# MDR1986VK01 register map
File version: 1.0.2
Registers are 32-bit, read-write, no defined reset value unless marked. A register's access mark holds for its fields unless they carry their own. Offsets are from the block's base; [hi:lo] are bit positions; {n}, {i} and the like mark numbered series; 'fields as' and 'values as' point back to an identical list.

## MDR_ADC0 — MDR_ADC0 description
Base 0x400A7000
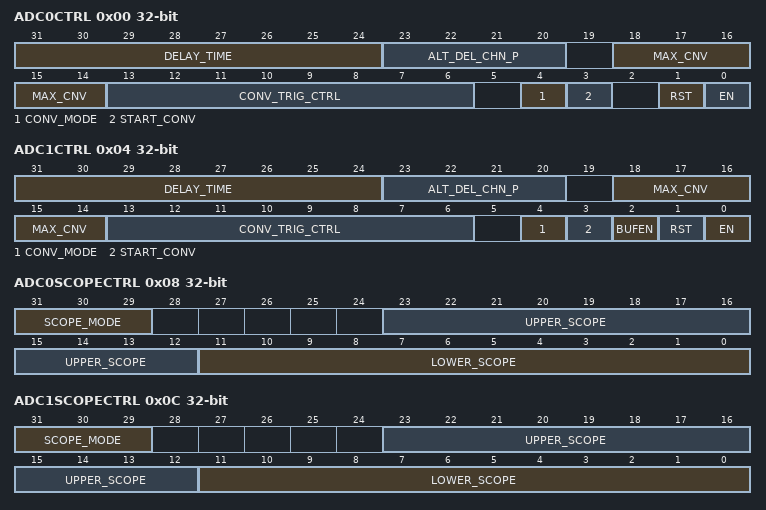
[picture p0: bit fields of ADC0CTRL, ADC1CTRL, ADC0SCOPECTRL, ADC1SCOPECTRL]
0x00 ADC0CTRL — ADC0CTRL description
  [31:24] DELAY_TIME — DELAY_TIME description
  [23:20] ALT_DEL_CHN_P — ALT_DEL_CHN_P description
  [18:14] MAX_CNV — MAX_CNV description
  [13:6] CONV_TRIG_CTRL — CONV_TRIG_CTRL description
  [4] CONV_MODE — CONV_MODE description
  [3] START_CONV — START_CONV description
  [1] RST — RST description
  [0] EN — EN description
0x04 ADC1CTRL — ADC1CTRL description
  [31:24] DELAY_TIME — DELAY_TIME description
  [23:20] ALT_DEL_CHN_P — ALT_DEL_CHN_P description
  [18:14] MAX_CNV — MAX_CNV description
  [13:6] CONV_TRIG_CTRL — CONV_TRIG_CTRL description
  [4] CONV_MODE — CONV_MODE description
  [3] START_CONV — START_CONV description
  [2] BUFEN — BUFEN description
  [1] RST — RST description
  [0] EN — EN description
0x08 ADC0SCOPECTRL — ADC0SCOPECTRL description
  [31:29] SCOPE_MODE — SCOPE_MODE description
  [23:12] UPPER_SCOPE — UPPER_SCOPE description
  [11:0] LOWER_SCOPE — LOWER_SCOPE description
0x0C ADC1SCOPECTRL — ADC1SCOPECTRL description
  fields as ADC0SCOPECTRL
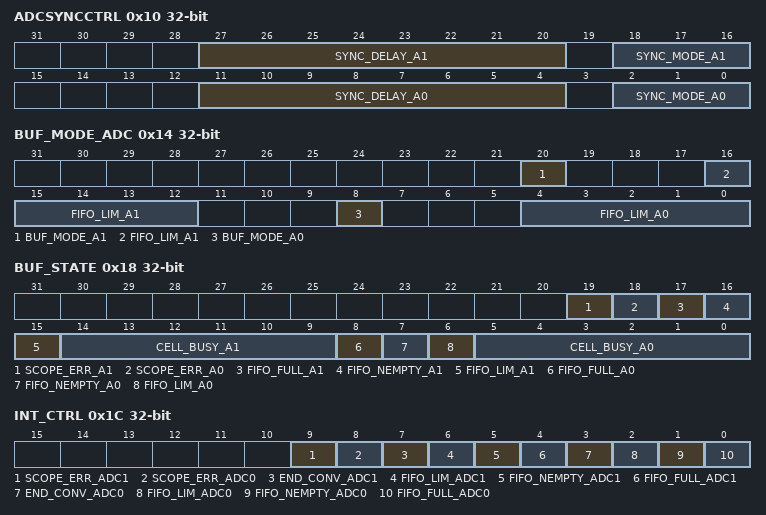
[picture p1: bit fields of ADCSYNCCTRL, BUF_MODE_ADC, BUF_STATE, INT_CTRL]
0x10 ADCSYNCCTRL — ADCSYNCCTRL description
  [27:20] SYNC_DELAY_A1 — SYNC_DELAY_A1 description
  [18:16] SYNC_MODE_A1 — SYNC_MODE_A1 description
  [11:4] SYNC_DELAY_A0 — SYNC_DELAY_A0 description
  [2:0] SYNC_MODE_A0 — SYNC_MODE_A0 description
0x14 BUF_MODE_ADC — BUF_MODE_ADC description
  [20] BUF_MODE_A1 — BUF_MODE_A1 description
  [16:12] FIFO_LIM_A1 — FIFO_LIM_A1 description
  [8] BUF_MODE_A0 — BUF_MODE_A0 description
  [4:0] FIFO_LIM_A0 — FIFO_LIM_A0 description
0x18 BUF_STATE — BUF_STATE description
  [19] SCOPE_ERR_A1 — SCOPE_ERR_A1 description
  [18] SCOPE_ERR_A0 — SCOPE_ERR_A0 description
  [17] FIFO_FULL_A1 — FIFO_FULL_A1 description
  [16] FIFO_NEMPTY_A1 — FIFO_NEMPTY_A1 description
  [15] FIFO_LIM_A1 — FIFO_LIM_A1 description
  [14:9] CELL_BUSY_A1 — CELL_BUSY_A1 description
  [8] FIFO_FULL_A0 — FIFO_FULL_A0 description
  [7] FIFO_NEMPTY_A0 — FIFO_NEMPTY_A0 description
  [6] FIFO_LIM_A0 — FIFO_LIM_A0 description
  [5:0] CELL_BUSY_A0 — CELL_BUSY_A0 description
0x1C INT_CTRL — INT_CTRL description
  [9] SCOPE_ERR_ADC1 — SCOPE_ERR_ADC1 description
  [8] SCOPE_ERR_ADC0 — SCOPE_ERR_ADC0 description
  [7] END_CONV_ADC1 — END_CONV_ADC1 description
  [6] FIFO_LIM_ADC1 — FIFO_LIM_ADC1 description
  [5] FIFO_NEMPTY_ADC1 — FIFO_NEMPTY_ADC1 description
  [4] FIFO_FULL_ADC1 — FIFO_FULL_ADC1 description
  [3] END_CONV_ADC0 — END_CONV_ADC0 description
  [2] FIFO_LIM_ADC0 — FIFO_LIM_ADC0 description
  [1] FIFO_NEMPTY_ADC0 — FIFO_NEMPTY_ADC0 description
  [0] FIFO_FULL_ADC0 — FIFO_FULL_ADC0 description
0x20 DMARQ_CTRL_ADC — DMARQ_CTRL_ADC description
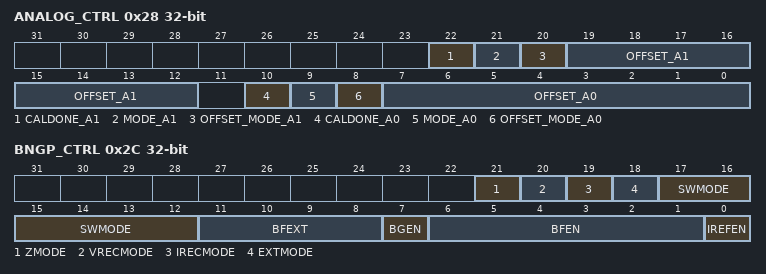
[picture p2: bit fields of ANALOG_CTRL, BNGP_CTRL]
0x28 ANALOG_CTRL — ANALOG_CTRL description
  [22] CALDONE_A1 — CALDONE_A1 description
  [21] MODE_A1 — MODE_A1 description
  [20] OFFSET_MODE_A1 — OFFSET_MODE_A1 description
  [19:12] OFFSET_A1 — OFFSET_A1 description
  [10] CALDONE_A0 — CALDONE_A0 description
  [9] MODE_A0 — MODE_A0 description
  [8] OFFSET_MODE_A0 — OFFSET_MODE_A0 description
  [7:0] OFFSET_A0 — OFFSET_A0 description
0x2C BNGP_CTRL — BNGP_CTRL description
  [21] ZMODE — ZMODE description
  [20] VRECMODE — VRECMODE description
  [19] IRECMODE — IRECMODE description
  [18] EXTMODE — EXTMODE description
  [17:12] SWMODE — SWMODE description
  [11:8] BFEXT — BFEXT description
  [7] BGEN — BGEN description
  [6:1] BFEN — BFEN description
  [0] IREFEN — IREFEN description
{0x40+4i} ADC0_CHNL_SEL{i} (i=0..7) — ADC0_CHNL_SEL{i} description
{0x60+4i} ADC1_CHNL_SEL{i} (i=0..7) — ADC1_CHNL_SEL{i} description
{0x80+4i} ADC0_RESULT{i} (i=0..31) — ADC0_RESULT{i} description
{0x100+4i} ADC1_RESULT{i} (i=0..31) — ADC1_RESULT{i} description

## MDR_ADC1 — MDR_ADC1 description
Base 0x400A8000
Registers as MDR_ADC0, without BNGP_CTRL.

## MDR_ADC2 — MDR_ADC2 description
Base 0x400A9000
Registers as MDR_ADC0, without BNGP_CTRL.
